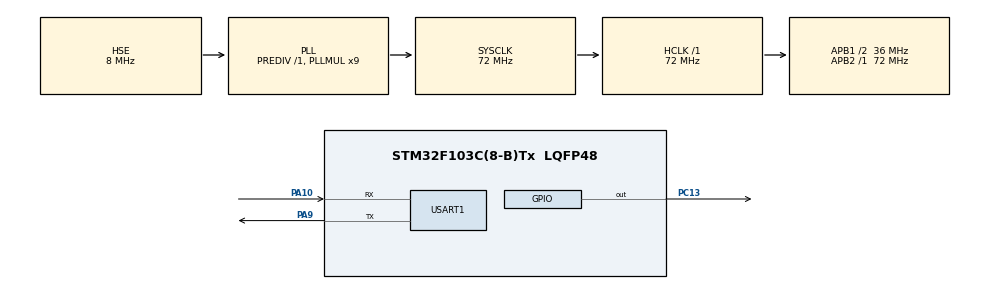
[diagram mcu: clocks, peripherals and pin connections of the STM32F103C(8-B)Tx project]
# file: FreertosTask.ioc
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Dma.Request0=USART1_RX
Dma.Request1=USART1_TX
Dma.USART1_RX.0.Direction=DMA_PERIPH_TO_MEMORY
Dma.USART1_RX.0.Instance=DMA1_Channel5
Dma.USART1_RX.0.MemDataAlignment=DMA_MDATAALIGN_BYTE
Dma.USART1_RX.0.MemInc=DMA_MINC_ENABLE
Dma.USART1_RX.0.Mode=DMA_NORMAL
Dma.USART1_RX.0.PeriphDataAlignment=DMA_PDATAALIGN_BYTE
Dma.USART1_RX.0.PeriphInc=DMA_PINC_DISABLE
Dma.USART1_RX.0.Priority=DMA_PRIORITY_LOW
Dma.USART1_TX.1.Direction=DMA_MEMORY_TO_PERIPH
Dma.USART1_TX.1.Instance=DMA1_Channel4
Dma.USART1_TX.1.MemDataAlignment=DMA_MDATAALIGN_BYTE
Dma.USART1_TX.1.MemInc=DMA_MINC_ENABLE
Dma.USART1_TX.1.Mode=DMA_NORMAL
Dma.USART1_TX.1.PeriphDataAlignment=DMA_PDATAALIGN_BYTE
Dma.USART1_TX.1.PeriphInc=DMA_PINC_DISABLE
Dma.USART1_TX.1.Priority=DMA_PRIORITY_LOW
FREERTOS.Tasks01=defaultTask,24,128,StartDefaultTask,Default,NULL,Dynamic,NULL,NULL
Mcu.Family=STM32F1
Mcu.Name=STM32F103C(8-B)Tx
Mcu.Package=LQFP48
NVIC.DMA1_Channel4_IRQn=true\:5\:0\:false\:false\:true\:true\:false\:true\:true
NVIC.DMA1_Channel5_IRQn=true\:5\:0\:false\:false\:true\:true\:false\:true\:true
NVIC.PriorityGroup=NVIC_PRIORITYGROUP_4
NVIC.TIM4_IRQn=true\:15\:0\:false\:false\:true\:false\:false\:true\:true
NVIC.TimeBase=TIM4_IRQn
NVIC.TimeBaseIP=TIM4
NVIC.USART1_IRQn=true\:5\:0\:false\:false\:true\:true\:false\:true\:true
PA10.Mode=Asynchronous
PA10.Signal=USART1_RX
PA13.Mode=Serial_Wire
PA13.Signal=SYS_JTMS-SWDIO
PA14.Mode=Serial_Wire
PA14.Signal=SYS_JTCK-SWCLK
PA9.Mode=Asynchronous
PA9.Signal=USART1_TX
PC13-TAMPER-RTC.Signal=GPIO_Output
PD0-OSC_IN.Mode=HSE-External-Oscillator
PD0-OSC_IN.Signal=RCC_OSC_IN
PD1-OSC_OUT.Mode=HSE-External-Oscillator
PD1-OSC_OUT.Signal=RCC_OSC_OUT
ProjectManager.HeapSize=0x200
ProjectManager.StackSize=0x400
ProjectManager.TargetToolchain=CMake
RCC.AHBFreq_Value=72000000
RCC.APB1CLKDivider=RCC_HCLK_DIV2
RCC.APB1Freq_Value=36000000
RCC.APB1TimFreq_Value=72000000
RCC.APB2Freq_Value=72000000
RCC.APB2TimFreq_Value=72000000
RCC.HCLKFreq_Value=72000000
RCC.PLLMUL=RCC_PLL_MUL9
RCC.PLLSourceVirtual=RCC_PLLSOURCE_HSE
RCC.SYSCLKFreq_VALUE=72000000
RCC.SYSCLKSource=RCC_SYSCLKSOURCE_PLLCLK
RCC.USBFreq_Value=72000000
USART1.VirtualMode=VM_ASYNC
VP_FREERTOS_VS_CMSIS_V2.Mode=CMSIS_V2
VP_SYS_VS_tim4.Mode=TIM4
board=custom

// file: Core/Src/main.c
/* USER CODE BEGIN Header */
/**
  ******************************************************************************
  * @file           : main.c
  * @brief          : Main program body
  ******************************************************************************
  * @attention
  *
  * Copyright (c) 2025 STMicroelectronics.
  * All rights reserved.
  *
  * This software is licensed under terms that can be found in the LICENSE file
  * in the root directory of this software component.
  * If no LICENSE file comes with this software, it is provided AS-IS.
  *
  ******************************************************************************
  */
/* USER CODE END Header */
#include "main.h"
#include "cmsis_os.h"
#include "stm32f1xx_hal_dma.h"
#include "stm32f1xx_hal_uart.h"

UART_HandleTypeDef huart1;
DMA_HandleTypeDef hdma_usart1_rx;
DMA_HandleTypeDef hdma_usart1_tx;

/* Definitions for defaultTask */

/* USER CODE BEGIN PV */
extern GolableVaribles varibles;

/* USER CODE END PV */

void SystemClock_Config(void);
static void MX_GPIO_Init(void);
static void MX_DMA_Init(void);
static void MX_USART1_UART_Init(void);

int main(void)
{

  /* MCU Configuration--------------------------------------------------------*/

  /* Reset of all peripherals, Initializes the Flash interface and the Systick. */
  HAL_Init();

  /* Configure the system clock */
  SystemClock_Config();

  /* Initialize all configured peripherals */
  MX_GPIO_Init();
  MX_DMA_Init();
  MX_USART1_UART_Init();
  /* USER CODE BEGIN 2 */
  HAL_UARTEx_ReceiveToIdle_DMA(&huart1, varibles.Rxbuffer, sizeof(varibles.Rxbuffer));
   __HAL_DMA_DISABLE_IT(&hdma_usart1_rx, DMA_IT_HT);
  /* USER CODE END 2 */

  /* Init scheduler */
  osKernelInitialize();

  /* USER CODE BEGIN RTOS_MUTEX */
  MX_FreeRTOS_Init();
  /* add mutexes, ... */
  /* USER CODE END RTOS_MUTEX */

  /* Create the thread(s) */
  /* creation of defaultTask */

  /* Start scheduler */
  osKernelStart();

  /* We should never get here as control is now taken by the scheduler */

  /* Infinite loop */
  while (1)
  {

  }
}

void SystemClock_Config(void)
{
  RCC_OscInitTypeDef RCC_OscInitStruct = {0};
  RCC_ClkInitTypeDef RCC_ClkInitStruct = {0};

  /** Initializes the RCC Oscillators according to the specified parameters
  * in the RCC_OscInitTypeDef structure.
  */
  RCC_OscInitStruct.OscillatorType = RCC_OSCILLATORTYPE_HSE;
  RCC_OscInitStruct.HSEState = RCC_HSE_ON;
  RCC_OscInitStruct.HSEPredivValue = RCC_HSE_PREDIV_DIV1;
  RCC_OscInitStruct.HSIState = RCC_HSI_ON;
  RCC_OscInitStruct.PLL.PLLState = RCC_PLL_ON;
  RCC_OscInitStruct.PLL.PLLSource = RCC_PLLSOURCE_HSE;
  RCC_OscInitStruct.PLL.PLLMUL = RCC_PLL_MUL9;
  if (HAL_RCC_OscConfig(&RCC_OscInitStruct) != HAL_OK)
  {
    Error_Handler();
  }

  /** Initializes the CPU, AHB and APB buses clocks
  */
  RCC_ClkInitStruct.ClockType = RCC_CLOCKTYPE_HCLK|RCC_CLOCKTYPE_SYSCLK
                              |RCC_CLOCKTYPE_PCLK1|RCC_CLOCKTYPE_PCLK2;
  RCC_ClkInitStruct.SYSCLKSource = RCC_SYSCLKSOURCE_PLLCLK;
  RCC_ClkInitStruct.AHBCLKDivider = RCC_SYSCLK_DIV1;
  RCC_ClkInitStruct.APB1CLKDivider = RCC_HCLK_DIV2;
  RCC_ClkInitStruct.APB2CLKDivider = RCC_HCLK_DIV1;

  if (HAL_RCC_ClockConfig(&RCC_ClkInitStruct, FLASH_LATENCY_2) != HAL_OK)
  {
    Error_Handler();
  }
}

static void MX_USART1_UART_Init(void)
{

  huart1.Instance = USART1;
  huart1.Init.BaudRate = 115200;
  huart1.Init.WordLength = UART_WORDLENGTH_8B;
  huart1.Init.StopBits = UART_STOPBITS_1;
  huart1.Init.Parity = UART_PARITY_NONE;
  huart1.Init.Mode = UART_MODE_TX_RX;
  huart1.Init.HwFlowCtl = UART_HWCONTROL_NONE;
  huart1.Init.OverSampling = UART_OVERSAMPLING_16;
  if (HAL_UART_Init(&huart1) != HAL_OK)
  {
    Error_Handler();
  }

}

static void MX_DMA_Init(void)
{

  /* DMA controller clock enable */
  __HAL_RCC_DMA1_CLK_ENABLE();

  /* DMA interrupt init */
  /* DMA1_Channel4_IRQn interrupt configuration */
  HAL_NVIC_SetPriority(DMA1_Channel4_IRQn, 5, 0);
  HAL_NVIC_EnableIRQ(DMA1_Channel4_IRQn);
  /* DMA1_Channel5_IRQn interrupt configuration */
  HAL_NVIC_SetPriority(DMA1_Channel5_IRQn, 5, 0);
  HAL_NVIC_EnableIRQ(DMA1_Channel5_IRQn);

}

static void MX_GPIO_Init(void)
{
  GPIO_InitTypeDef GPIO_InitStruct = {0};

  /* GPIO Ports Clock Enable */
  __HAL_RCC_GPIOC_CLK_ENABLE();
  __HAL_RCC_GPIOD_CLK_ENABLE();
  __HAL_RCC_GPIOA_CLK_ENABLE();

  /*Configure GPIO pin Output Level */
  HAL_GPIO_WritePin(GPIOC, GPIO_PIN_13, GPIO_PIN_RESET);

  /*Configure GPIO pin : PC13 */
  GPIO_InitStruct.Pin = GPIO_PIN_13;
  GPIO_InitStruct.Mode = GPIO_MODE_OUTPUT_PP;
  GPIO_InitStruct.Pull = GPIO_NOPULL;
  GPIO_InitStruct.Speed = GPIO_SPEED_FREQ_LOW;
  HAL_GPIO_Init(GPIOC, &GPIO_InitStruct);

}

/* USER CODE BEGIN 4 */
void HAL_UARTEx_RxEventCallback(UART_HandleTypeDef *huart, uint16_t Size)
{
  varibles.flag = 1;
  varibles.len = Size;

  HAL_UARTEx_ReceiveToIdle_DMA(&huart1, varibles.Rxbuffer, sizeof(varibles.Rxbuffer));
   __HAL_DMA_DISABLE_IT(&hdma_usart1_rx, DMA_IT_HT);
}

/* USER CODE END 4 */

void HAL_TIM_PeriodElapsedCallback(TIM_HandleTypeDef *htim)
{
  if (htim->Instance == TIM4)
  {
    HAL_IncTick();
  }
}

void Error_Handler(void)
{
  __disable_irq();
  while (1)
  {
  }
}

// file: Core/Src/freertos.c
/* USER CODE BEGIN Header */
/**
  ******************************************************************************
  * File Name          : freertos.c
  * Description        : Code for freertos applications
  ******************************************************************************
  * @attention
  *
  * Copyright (c) 2025 STMicroelectronics.
  * All rights reserved.
  *
  * This software is licensed under terms that can be found in the LICENSE file
  * in the root directory of this software component.
  * If no LICENSE file comes with this software, it is provided AS-IS.
  *
  ******************************************************************************
  */
/* USER CODE END Header */

#include "FreeRTOS.h"
#include "cmsis_os2.h"
#include "task.h"
#include "main.h"
#include "queue.h"
#include <string.h>

/* USER CODE BEGIN PTD */
TaskHandle_t xLedCtrlHandle;
TaskHandle_t xCalcuHandle;
QueueHandle_t xPointerQueue = NULL;
GolableVaribles varibles;
/* USER CODE END PTD */

/* USER CODE BEGIN PD */
void SendData(int data)
{
  if(xPointerQueue == NULL) {
    return;
  }
  xQueueSend(xPointerQueue, &data, portMAX_DELAY);

}
/* USER CODE END PD */

/* USER CODE BEGIN Variables */
int speed = 500;//[1,32767]

/* USER CODE END Variables */

/* USER CODE BEGIN FunctionPrototypes */
void CalcuFunction(void *Param)
{
  int temp = 0;
  while(1)
  {
  if(varibles.flag)
  {
    temp = 0;
    for(int i = 0;i < varibles.len;i++)
    {
      if('0' <= varibles.Rxbuffer[i] && varibles.Rxbuffer[i] <= '9')
      {
        temp = temp*10 + (varibles.Rxbuffer[i] - '0');
      }
    }
    varibles.flag = 0;
    SendData(temp);
    memset(varibles.Rxbuffer,0,sizeof(varibles.Rxbuffer));
  }
}
}

void LedCtrlFunction(void *Param)
{
  int temp = 0;
  while(1)
  {
  if(xPointerQueue != NULL){
  if(xQueueReceive(xPointerQueue, &temp,0) == pdPASS)
  {
      speed = temp;
      temp = 0;
  }
  }
  HAL_GPIO_TogglePin(GPIOC, GPIO_PIN_13);
  osDelay(speed);
  }
}

/* USER CODE END FunctionPrototypes */

/* USER CODE BEGIN Application */
void MX_FreeRTOS_Init()
{
  xPointerQueue = xQueueCreate(1, sizeof(int));

  xTaskCreate(CalcuFunction, "Calcu", 128, NULL, 1, &xCalcuHandle);
  xTaskCreate(LedCtrlFunction, "LedCtrl", 128, NULL, 2, &xLedCtrlHandle);
}

/* USER CODE END Application */
